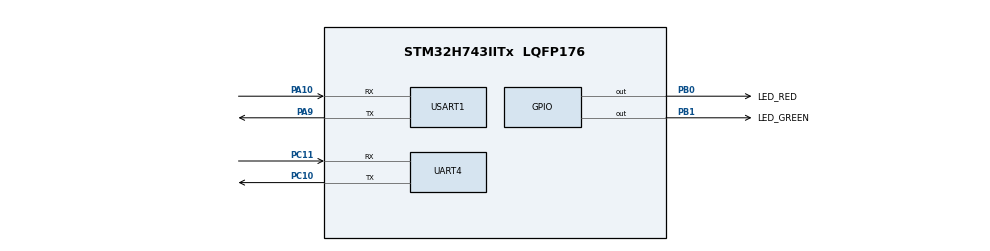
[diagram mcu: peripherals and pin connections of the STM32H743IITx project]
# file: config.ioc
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CORTEX_M7.AccessPermission_Spec=MPU_REGION_FULL_ACCESS
CORTEX_M7.DisableExec_Spec=MPU_INSTRUCTION_ACCESS_ENABLE
CORTEX_M7.IsShareable_Spec=MPU_ACCESS_SHAREABLE
CORTEX_M7.SubRegionDisable_Spec=0x0
CORTEX_M7.default_mode_Activation=1
Dma.Request0=UART4_RX
Dma.UART4_RX.0.Direction=DMA_PERIPH_TO_MEMORY
Dma.UART4_RX.0.EventEnable=DISABLE
Dma.UART4_RX.0.FIFOMode=DMA_FIFOMODE_DISABLE
Dma.UART4_RX.0.Instance=DMA1_Stream0
Dma.UART4_RX.0.MemDataAlignment=DMA_MDATAALIGN_BYTE
Dma.UART4_RX.0.MemInc=DMA_MINC_ENABLE
Dma.UART4_RX.0.Mode=DMA_CIRCULAR
Dma.UART4_RX.0.PeriphDataAlignment=DMA_PDATAALIGN_BYTE
Dma.UART4_RX.0.PeriphInc=DMA_PINC_DISABLE
Dma.UART4_RX.0.Polarity=HAL_DMAMUX_REQ_GEN_RISING
Dma.UART4_RX.0.Priority=DMA_PRIORITY_VERY_HIGH
Dma.UART4_RX.0.RequestNumber=1
Dma.UART4_RX.0.SignalID=NONE
Dma.UART4_RX.0.SyncEnable=DISABLE
Dma.UART4_RX.0.SyncPolarity=HAL_DMAMUX_SYNC_NO_EVENT
Dma.UART4_RX.0.SyncRequestNumber=1
Dma.UART4_RX.0.SyncSignalID=NONE
LPTIM1.ClockPrescaler=LPTIM_PRESCALER_DIV4
Mcu.Family=STM32H7
Mcu.Name=STM32H743IITx
Mcu.Package=LQFP176
NVIC.DMA1_Stream0_IRQn=true\:6\:0\:true\:false\:false\:false\:true\:true
NVIC.PriorityGroup=NVIC_PRIORITYGROUP_3
NVIC.UART4_IRQn=true\:7\:0\:true\:false\:false\:true\:true\:true
NVIC.USART1_IRQn=true\:7\:1\:true\:false\:true\:true\:true\:true
PA10.GPIO_Speed=GPIO_SPEED_FREQ_VERY_HIGH
PA10.Mode=Asynchronous
PA10.Signal=USART1_RX
PA13\ (JTMS/SWDIO).Mode=Serial_Wire
PA13\ (JTMS/SWDIO).Signal=DEBUG_JTMS-SWDIO
PA14\ (JTCK/SWCLK).Mode=Serial_Wire
PA14\ (JTCK/SWCLK).Signal=DEBUG_JTCK-SWCLK
PA9.GPIO_Speed=GPIO_SPEED_FREQ_VERY_HIGH
PA9.Mode=Asynchronous
PA9.Signal=USART1_TX
PB0.GPIO_Label=LED_RED
PB0.PinState=GPIO_PIN_SET
PB0.Signal=GPIO_Output
PB1.GPIO_Label=LED_GREEN
PB1.PinState=GPIO_PIN_SET
PB1.Signal=GPIO_Output
PC10.GPIO_Speed=GPIO_SPEED_FREQ_VERY_HIGH
PC10.Mode=Asynchronous
PC10.Signal=UART4_TX
PC11.GPIO_Speed=GPIO_SPEED_FREQ_VERY_HIGH
PC11.Mode=Asynchronous
PC11.Signal=UART4_RX
PH0-OSC_IN\ (PH0).Mode=HSE-External-Oscillator
PH0-OSC_IN\ (PH0).Signal=RCC_OSC_IN
PH1-OSC_OUT\ (PH1).Mode=HSE-External-Oscillator
PH1-OSC_OUT\ (PH1).Signal=RCC_OSC_OUT
ProjectManager.HeapSize=0x0
ProjectManager.StackSize=0x400
ProjectManager.TargetToolchain=CMake
RCC.ADCFreq_Value=50390625
RCC.APB1Freq_Value=120000000
RCC.APB2Freq_Value=120000000
RCC.APB3Freq_Value=120000000
RCC.APB4Freq_Value=120000000
RCC.CKPERSourceSelection=RCC_CLKPSOURCE_CSI
RCC.CortexFreq_Value=480000000
RCC.D1PPRE=RCC_APB3_DIV2
RCC.D2PPRE1=RCC_APB1_DIV2
RCC.D2PPRE2=RCC_APB2_DIV2
RCC.D3PPRE=RCC_APB4_DIV2
RCC.DIVM1=5
RCC.DIVN1=192
RCC.EnbaleCSS=true
RCC.HCLKFreq_Value=240000000
RCC.HPRE=RCC_HCLK_DIV2
RCC.LPTIM1CLockSelection=RCC_LPTIM1CLKSOURCE_CLKP
RCC.PLLSourceVirtual=RCC_PLLSOURCE_HSE
RCC.SYSCLKFreq_VALUE=480000000
RCC.SYSCLKSource=RCC_SYSCLKSOURCE_PLLCLK
RCC.USBFreq_Value=480000000
UART4.DMADisableonRxErrorParam=UART_ADVFEATURE_DMA_DISABLEONRXERROR
UART4.FIFOMode=FIFOMODE_ENABLE
UART4.OverrunDisableParam=UART_ADVFEATURE_OVERRUN_DISABLE
UART4.RXFIFOThreshold=RXFIFO_THRESHOLD_HALFFULL
UART4.TXFIFOThreshold=TXFIFO_THRESHOLD_HALFFULL
USART1.DMADisableonRxErrorParam=ADVFEATURE_DMA_DISABLEONRXERROR
USART1.OverrunDisableParam=ADVFEATURE_OVERRUN_DISABLE
USART1.VirtualMode-Asynchronous=VM_ASYNC
VP_LPTIM1_VS_LPTIM_counterModeInternalClock.Mode=Counts__internal_clock_event_00
VP_MEMORYMAP_VS_MEMORYMAP.Mode=CurAppReg
board=custom

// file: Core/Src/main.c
/* USER CODE BEGIN Header */
/**
  ******************************************************************************
  * @file           : main.c
  * @brief          : Main program body
  ******************************************************************************
  * @attention
  *
  * Copyright (c) 2026 STMicroelectronics.
  * All rights reserved.
  *
  * This software is licensed under terms that can be found in the LICENSE file
  * in the root directory of this software component.
  * If no LICENSE file comes with this software, it is provided AS-IS.
  *
  ******************************************************************************
  */
/* USER CODE END Header */
#include "main.h"
#include "dma.h"
#include "lptim.h"
#include "usart.h"
#include "gpio.h"

void SystemClock_Config(void);
void PeriphCommonClock_Config(void);
static void MPU_Config(void);

int main(void)
{

  /* MPU Configuration--------------------------------------------------------*/
  MPU_Config();

  /* MCU Configuration--------------------------------------------------------*/

  /* Reset of all peripherals, Initializes the Flash interface and the Systick. */
  HAL_Init();

  /* Configure the system clock */
  SystemClock_Config();

  /* Configure the peripherals common clocks */
  PeriphCommonClock_Config();

  /* Initialize all configured peripherals */
  MX_GPIO_Init();
  MX_DMA_Init();
  MX_USART1_UART_Init();
  MX_UART4_Init();
  MX_LPTIM1_Init();

  /* Infinite loop */
  /* USER CODE BEGIN WHILE */
#if 0
  while (1)
  {
    HAL_GPIO_TogglePin(LED_RED_GPIO_Port, LED_RED_Pin);
    HAL_GPIO_TogglePin(LED_GREEN_GPIO_Port, LED_GREEN_Pin);
    HAL_Delay(500);
    /* USER CODE END WHILE */

    /* USER CODE BEGIN 3 */
  }
#endif
  return 0;
  /* USER CODE END 3 */
}

void SystemClock_Config(void)
{
  LL_FLASH_SetLatency(LL_FLASH_LATENCY_4);
  while(LL_FLASH_GetLatency()!= LL_FLASH_LATENCY_4)
  {
  }
  LL_PWR_ConfigSupply(LL_PWR_LDO_SUPPLY);
  LL_PWR_SetRegulVoltageScaling(LL_PWR_REGU_VOLTAGE_SCALE0);
  while (LL_PWR_IsActiveFlag_VOS() == 0)
  {
  }
  LL_RCC_HSE_Enable();

   /* Wait till HSE is ready */
  while(LL_RCC_HSE_IsReady() != 1)
  {

  }
  LL_RCC_CSI_Enable();

   /* Wait till LSI is ready */
  while(LL_RCC_CSI_IsReady() != 1)
  {
  }

  LL_RCC_HSE_EnableCSS();
  LL_RCC_PLL_SetSource(LL_RCC_PLLSOURCE_HSE);
  LL_RCC_PLL1P_Enable();
  LL_RCC_PLL1R_Enable();
  LL_RCC_PLL1_SetVCOInputRange(LL_RCC_PLLINPUTRANGE_4_8);
  LL_RCC_PLL1_SetVCOOutputRange(LL_RCC_PLLVCORANGE_WIDE);
  LL_RCC_PLL1_SetM(5);
  LL_RCC_PLL1_SetN(192);
  LL_RCC_PLL1_SetP(2);
  LL_RCC_PLL1_SetQ(2);
  LL_RCC_PLL1_SetR(2);
  LL_RCC_PLL1_Enable();

   /* Wait till PLL is ready */
  while(LL_RCC_PLL1_IsReady() != 1)
  {
  }

   /* Intermediate AHB prescaler 2 when target frequency clock is higher than 80 MHz */
   LL_RCC_SetAHBPrescaler(LL_RCC_AHB_DIV_2);

  LL_RCC_SetSysClkSource(LL_RCC_SYS_CLKSOURCE_PLL1);

   /* Wait till System clock is ready */
  while(LL_RCC_GetSysClkSource() != LL_RCC_SYS_CLKSOURCE_STATUS_PLL1)
  {

  }
  LL_RCC_SetSysPrescaler(LL_RCC_SYSCLK_DIV_1);
  LL_RCC_SetAHBPrescaler(LL_RCC_AHB_DIV_2);
  LL_RCC_SetAPB1Prescaler(LL_RCC_APB1_DIV_2);
  LL_RCC_SetAPB2Prescaler(LL_RCC_APB2_DIV_2);
  LL_RCC_SetAPB3Prescaler(LL_RCC_APB3_DIV_2);
  LL_RCC_SetAPB4Prescaler(LL_RCC_APB4_DIV_2);
  LL_SetSystemCoreClock(480000000);

   /* Update the time base */
  if (HAL_InitTick (TICK_INT_PRIORITY) != HAL_OK)
  {
    Error_Handler();
  }
  LL_RCC_HSE_EnableCSS();
}

void PeriphCommonClock_Config(void)
{
  LL_RCC_SetCLKPClockSource(LL_RCC_CLKP_CLKSOURCE_CSI);
}

 /* MPU Configuration */

void MPU_Config(void)
{
  MPU_Region_InitTypeDef MPU_InitStruct = {0};

  /* Disables the MPU */
  HAL_MPU_Disable();

  /** Initializes and configures the Region and the memory to be protected
  */
  MPU_InitStruct.Enable = MPU_REGION_ENABLE;
  MPU_InitStruct.Number = MPU_REGION_NUMBER0;
  MPU_InitStruct.BaseAddress = 0x0;
  MPU_InitStruct.Size = MPU_REGION_SIZE_4GB;
  MPU_InitStruct.SubRegionDisable = 0x0;
  MPU_InitStruct.TypeExtField = MPU_TEX_LEVEL0;
  MPU_InitStruct.AccessPermission = MPU_REGION_FULL_ACCESS;
  MPU_InitStruct.DisableExec = MPU_INSTRUCTION_ACCESS_ENABLE;
  MPU_InitStruct.IsShareable = MPU_ACCESS_SHAREABLE;
  MPU_InitStruct.IsCacheable = MPU_ACCESS_NOT_CACHEABLE;
  MPU_InitStruct.IsBufferable = MPU_ACCESS_NOT_BUFFERABLE;

  HAL_MPU_ConfigRegion(&MPU_InitStruct);
  /* Enables the MPU */
  HAL_MPU_Enable(MPU_PRIVILEGED_DEFAULT);

}

void Error_Handler(void)
{
  __disable_irq();
  while (1)
  {
  }
}
